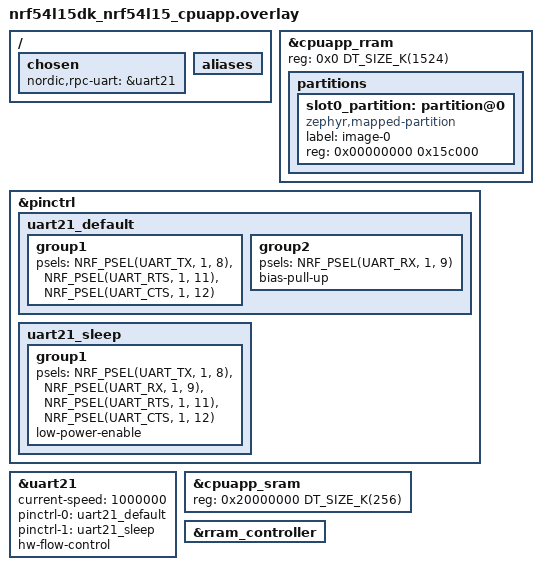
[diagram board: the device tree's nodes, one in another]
/*
 * Copyright (c) 2026 Nordic Semiconductor ASA
 *
 * SPDX-License-Identifier: LicenseRef-Nordic-5-Clause
 *
 * RPC over UART21 @ 1 Mbps with HW flow control (nRF RPC serialization reference).
 *
 * nRF54L15 DK (application core) UART21: RX P1.09, TX P1.08, RTS P1.11, CTS P1.12.
 * Cross-connect to nRF9151 DK server RPC UART (P0.10–P0.13).
 *
 * Frees GPIO used by UART21 by removing buttons 1–3 from devicetree.
 */

/ {
	chosen {
		nordic,rpc-uart = &uart21;
	};

	aliases {
		/delete-property/ sw1;
		/delete-property/ sw2;
		/delete-property/ sw3;
	};
};

/delete-node/ &button1;
/delete-node/ &button2;
/delete-node/ &button3;
/delete-node/ &boot_partition;
/delete-node/ &slot0_partition;
/delete-node/ &slot1_partition;

&cpuapp_rram {
	reg = <0x0 DT_SIZE_K(1524)>;

	partitions {
		slot0_partition: partition@0 {
			compatible = "zephyr,mapped-partition";
			label = "image-0";
			reg = <0x00000000 0x15c000>;
		};
	};
};

&pinctrl {
	uart21_default: uart21_default {
		group1 {
			psels = <NRF_PSEL(UART_TX, 1, 8)>,
				<NRF_PSEL(UART_RTS, 1, 11)>,
				<NRF_PSEL(UART_CTS, 1, 12)>;
		};

		group2 {
			psels = <NRF_PSEL(UART_RX, 1, 9)>;
			bias-pull-up;
		};
	};

	uart21_sleep: uart21_sleep {
		group1 {
			psels = <NRF_PSEL(UART_TX, 1, 8)>,
				<NRF_PSEL(UART_RX, 1, 9)>,
				<NRF_PSEL(UART_RTS, 1, 11)>,
				<NRF_PSEL(UART_CTS, 1, 12)>;
			low-power-enable;
		};
	};
};

&uart21 {
	status = "okay";
	current-speed = <1000000>;
	pinctrl-0 = <&uart21_default>;
	pinctrl-1 = <&uart21_sleep>;
	pinctrl-names = "default", "sleep";
	hw-flow-control;
};

&cpuapp_sram {
	reg = <0x20000000 DT_SIZE_K(256)>;
	ranges = <0x0 0x20000000 0x40000>;
};

&rram_controller {
	/delete-node/ cpuflpr_sram;
	/delete-node/ cpuflpr_rram;
};
